# Global_Reg_PRM register map
Vendor: Texas Instruments
Peripheral module from a debugger description file (folder omap34xx).
Registers are 32-bit, access per field, reset values left out (the file's numbers can be read two ways) unless marked. A register's access mark holds for its fields unless they carry their own. Offsets are as the file gives them; lines under a group give offsets from that group; [hi:lo] are bit positions; {n}, {i} and the like mark numbered series; 'fields as' and 'values as' point back to an identical list; <NAME> marks a mode.

## Global_Reg_PRM
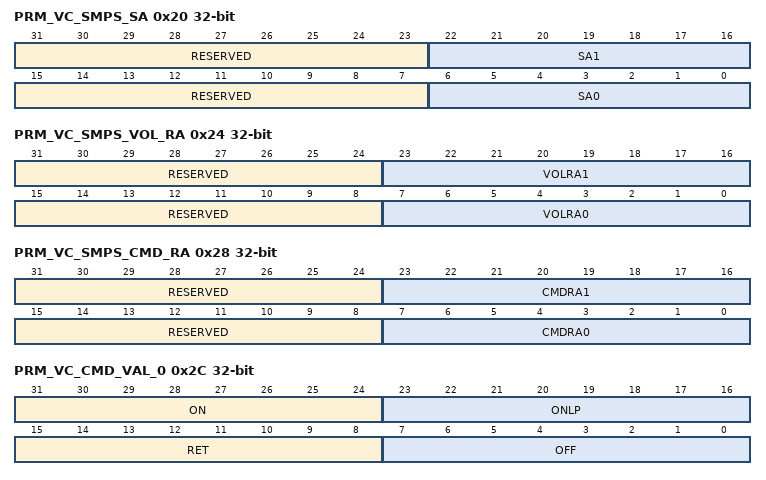
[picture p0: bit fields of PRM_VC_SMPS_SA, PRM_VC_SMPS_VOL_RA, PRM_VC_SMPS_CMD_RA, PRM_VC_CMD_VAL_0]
0x20 PRM_VC_SMPS_SA — This register allows the setting of the I2C slave address of the Power IC device.
  [31:23] RESERVED ro — Write 0s for future compatibility. Read is undefined.
  [22:16] SA1 rw — Set the IC slave address value for the second (if any) Power IC device.
  [15:7] RESERVED ro — Write 0s for future compatibility. Read is undefined.
  [6:0] SA0 rw — Set the IC slave address value for the first Power IC device.
0x24 PRM_VC_SMPS_VOL_RA — This register allows the setting of the voltage configuration register address for the VDD channels.
  [31:24] RESERVED ro — Write 0s for future compatibility. Read is undefined.
  [23:16] VOLRA1 rw — Set the voltage configuration register address value for the second VDD channel (VDD2).
  [15:8] RESERVED ro — Write 0s for future compatibility. Read is undefined.
  [7:0] VOLRA0 rw — Set the voltage configuration register address value for the first VDD channel (VDD1).
0x28 PRM_VC_SMPS_CMD_RA — This register allows the setting of the ON/Retention/OFF command configuration register address for the VDD channels. It is used if the Power IC device has different register addresses for voltage value and ON/Retention/OFF command.
  [31:24] RESERVED ro — Write 0s for future compatibility. Read is undefined.
  [23:16] CMDRA1 rw — Set the ON/ON-LP/Retention/OFF command configuration register address value for the second VDD channel (VDD2).
  [15:8] RESERVED ro — Write 0s for future compatibility. Read is undefined.
  [7:0] CMDRA0 rw — Set the ON/ON-LP/Retention/OFF command configuration register address value for the first VDD channel (VDD1).
0x2C PRM_VC_CMD_VAL_0 rw — This register allows the setting of the ON/Retention/OFF voltage level values for the first VDD channel.
  [31:24] ON — Set the ON voltage level value for the first VDD channel (VDD1).
  [23:16] ONLP — Set the ON-LP voltage level value for the first VDD channel (VDD1).
  [15:8] RET — Set the RET voltage level value for the first VDD channel (VDD1).
  [7:0] OFF — Set the OFF voltage level value for the first VDD channel (VDD1).
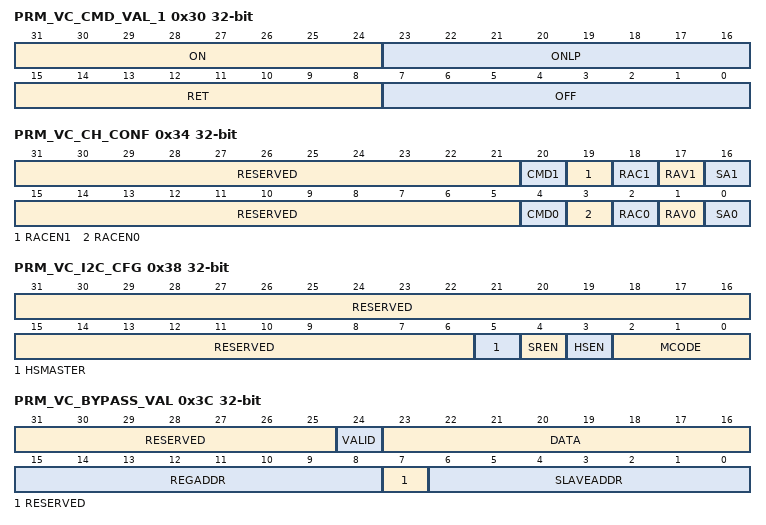
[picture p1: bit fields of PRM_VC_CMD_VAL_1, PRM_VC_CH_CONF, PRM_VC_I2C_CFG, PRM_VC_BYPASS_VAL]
0x30 PRM_VC_CMD_VAL_1 rw — This register allows the setting of the ON/Retention/OFF voltage level values for the second VDD channel. It is used if the second channel has different values than the first channel.
  [31:24] ON — Set the ON voltage level value for the second VDD channel (VDD2).
  [23:16] ONLP — Set the ON-LP voltage level value for the second VDD channel (VDD2).
  [15:8] RET — Set the RET voltage level value for the second VDD channel (VDD2).
  [7:0] OFF — Set the OFF voltage level value for the second VDD channel (VDD2).
0x34 PRM_VC_CH_CONF — This register allows the configuration pointers for both VDD channels.
  [31:21] RESERVED ro — Write 0s for future compatibility. Read is undefined.
  [20] CMD1 rw — Selects the ON/ON-LP/Retention/OFF voltage values for the second VDD channel (VDD2).
  [19] RACEN1 rw — Enable bit for usage of RAC1.
  [18] RAC1 rw — Set the ON/ON-LP/Retention/OFF command configuration register address pointer for the second VDD channel (VDD2).
  [17] RAV1 rw — Set the voltage configuration register address pointer for the second VDD channel (VDD2).
  [16] SA1 rw — Set the slave address pointer for the second VDD channel (VDD2).
  [15:5] RESERVED ro — Write 0s for future compatibility. Read is undefined.
  [4] CMD0 rw — Selects the ON/ON-LP/Retention/OFF voltage values for the first VDD channel (VDD1).
  [3] RACEN0 rw — Enable bit for usage of RAC0.
  [2] RAC0 rw — Set the ON/ON-LP/Retention/OFF command configuration register address pointer for the first VDD channel (VDD1).
  [1] RAV0 rw — Set the voltage configuration register address pointer for the first VDD channel (VDD1).
  [0] SA0 rw — Set the slave address pointer for the first VDD channel (VDD1).
0x38 PRM_VC_I2C_CFG — This register allows the configuration pointers for both VDD channels.
  [31:6] RESERVED ro — Write 0s for future compatibility. Read is undefined.
  [5] HSMASTER rw — Put the I2C pads in a low power mode in case of light load.
    0=Disables the I2C pads low power mode; 1=Enables the I2C pads low power mode
  [4] SREN rw — Enables the I2C repeated start operation mode.
    0=Disables the repeated start operation mode; 1=Enables the repeated start operation mode
  [3] HSEN rw — Enables I2C bus High Speed mode.
    0=Disables the I2C high speed mode; 1=Enables the I2C high speed mode
  [2:0] MCODE rw — Master code value for I2C High Speed preamble transmission.
0x3C PRM_VC_BYPASS_VAL rw — This register allows the programming of the Power IC device using the bypass interface.
  [31:25] RESERVED — Write 0s for future compatibility. Read is undefined.
  [24] VALID — This bit validates the bypass command. It is automatically cleared by HW either after getting the acknowledge back from the SMPS or if an error occured.
    0=The last command send has been acknowledged; 1=The Voltage Controller send the command to the I2C interface; 1=Pending command is being process
  [23:16] DATA — Data to send to the Power IC device.
  [15:8] REGADDR — Set the address of Power IC device register to configure.
  [7] RESERVED — Write 0s for future compatibility. Read is undefined.
  [6:0] SLAVEADDR — Set the I2C slave address value.
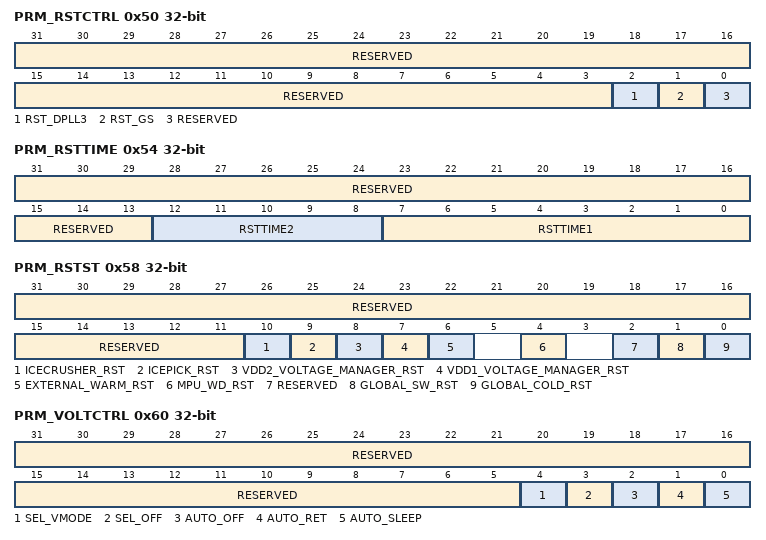
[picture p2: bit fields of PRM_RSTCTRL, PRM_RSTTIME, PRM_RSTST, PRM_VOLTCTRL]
0x50 PRM_RSTCTRL — Global software and DPLL3 reset control. This register is auto-cleared. Only write 1 is possible. A read returns 0 only.
  [31:3] RESERVED ro — Write 0s for future compatibility. Read returns 0.
  [2] RST_DPLL3 rw — DPLL3 software reset control. This bit is reset only upon a global cold source of reset.
    0=DPLL3 software reset is cleared; 1=Asserts the DPLL3 software reset and induces a global cold reset on the whole chip. The software must ensure the SDRAM is properly put in sef-refresh mode before applying this reset.
  [1] RST_GS rw — Global software reset control. This bit is reset upon any global source of reset (warm and cold).
    0=Global software reset is cleared; 1=Asserts a global software reset
  [0] RESERVED ro — Write 0s for future compatibility. Read returns 0.
0x54 PRM_RSTTIME — Reset duration control.
  [31:13] RESERVED ro — Write 0s for future compatibility. Read returns 0.
  [12:8] RSTTIME2 rw — (Power domain) reset duration 2(number of RM_ICLK clock cycles)
  [7:0] RSTTIME1 rw — (Global) reset duration 1(number of Func_32k.clk clock cycles)
0x58 PRM_RSTST — This register logs the global reset sources. Each bit is set upon release of the domain reset signal. Must be cleared by software.
  [31:11] RESERVED ro — Write 0s for future compatibility. Read returns 0.
  [10] ICECRUSHER_RST rw — IceCrusher reset event. This is a source of warm reset initiated by the emulation.
    0=ICECRUSHER_RST_0_r (No IceCrusher reset.); 0=ICECRUSHER_RST_0_w (Status bit unchanged); 1=ICECRUSHER_RST_1_r (IceCrusher reset occurred.); 1=ICECRUSHER_RST_1_w (Status bit is cleared to 0.)
  [9] ICEPICK_RST rw — IcePick reset event. This is a source of warm reset initiated by the emulation.
    0=ICEPICK_RST_0_r (No IcePick reset.); 0=ICEPICK_RST_0_w (Status bit unchanged); 1=ICEPICK_RST_1_r (IcePick reset occurred.); 1=ICEPICK_RST_1_w (Status bit is cleared to 0.)
  [8] VDD2_VOLTAGE_MANAGER_RST rw — VDD2 voltage manager reset event
    0=VDD2_VOLTAGE_MANAGER_RST_0_r (No VDD2 voltage manager reset.); 0=VDD2_VOLTAGE_MANAGER_RST_0_w (Status bit unchanged); 1=VDD2_VOLTAGE_MANAGER_RST_1_r (VDD2 voltage manager reset occurred.); 1=VDD2_VOLTAGE_MANAGER_RST_1_w (Status bit is cleared to 0.)
  [7] VDD1_VOLTAGE_MANAGER_RST rw — VDD1 voltage manager reset event
    0=VDD1_VOLTAGE_MANAGER_RST_0_r (No VDD1 voltage manager reset.); 0=VDD1_VOLTAGE_MANAGER_RST_0_w (Status bit unchanged); 1=VDD1_VOLTAGE_MANAGER_RST_1_r (VDD1 voltage manager reset occurred.); 1=VDD1_VOLTAGE_MANAGER_RST_1_w (Status bit is cleared to 0.)
  [6] EXTERNAL_WARM_RST rw — External warm reset event
    0=EXTERNAL_WARM_RST_0_r (No global warm reset.); 0=EXTERNAL_WARM_RST_0_w (Status bit unchanged); 1=EXTERNAL_WARM_RST_1_r (Global external warm reset occurred.); 1=EXTERNAL_WARM_RST_1_w (Status bit is cleared to 0.)
  [4] MPU_WD_RST rw — MPU watchdog reset event
    0=MPU_WD_RST_0_r (No MPU watchdog reset.); 0=MPU_WD_RST_0_w (Status bit unchanged); 1=MPU_WD_RST_1_r (MPU wachtdog reset occurred.); 1=MPU_WD_RST_1_w (Status bit is cleared to 0.)
  [2] RESERVED ro — Write 0s for future compatibility. Read returns 0.
  [1] GLOBAL_SW_RST rw — Global software reset event
    0=GLOBAL_SW_RST_0_r (No global software reset.); 0=GLOBAL_SW_RST_0_w (Status bit unchanged); 1=GLOBAL_SW_RST_1_r (Global software reset occurred.); 1=GLOBAL_SW_RST_1_w (Status bit is cleared to 0.)
  [0] GLOBAL_COLD_RST rw — Power-up (cold) reset event
    0=GLOBAL_COLD_RST_0_r (No power-on reset.); 0=GLOBAL_COLD_RST_0_w (Status bit unchanged); 1=GLOBAL_COLD_RST_1_r (Power-on reset occurred.); 1=GLOBAL_COLD_RST_1_w (Status bit is cleared to 0.)
0x60 PRM_VOLTCTRL — This register allows a direct control on the external power IC.
  [31:5] RESERVED ro — Write 0s for future compatibility. Read returns 0.
  [4] SEL_VMODE rw — This bit allows to select the mode used to control the Power IC (I2C or VMODE).
    0=The Power IC is controlled through the I2C interface; 1=The Power IC is controlled through the VMODE interface
  [3] SEL_OFF rw — This bit allows to select the mode used to send the OFF command.
    0=The OFF command is sent through the voltage controller I2C interface; 1=The signal SYS.OFF_MODE is asserted
  [2] AUTO_OFF rw — This bit allows to send an OFF command to the Power IC.
    0=The OFF command is not sent; 1=The OFF command is automatically send when the voltage domain is in the appropriate standby mode
  [1] AUTO_RET rw — This bit allows to send a RETENTION command to the Power IC through the voltage controller I2C interface.
    0=The RETENTION command is not sent; 1=The RETENTION command is automatically send when the voltage domain is in the appropriate standby mode
  [0] AUTO_SLEEP rw — This bit allows to send a SLEEP command to the Power IC through the voltage controller I2C interface.
    0=The SLEEP command is not sent; 1=The SLEEP command is automatically send when the voltage domain is in the appropriate standby mode
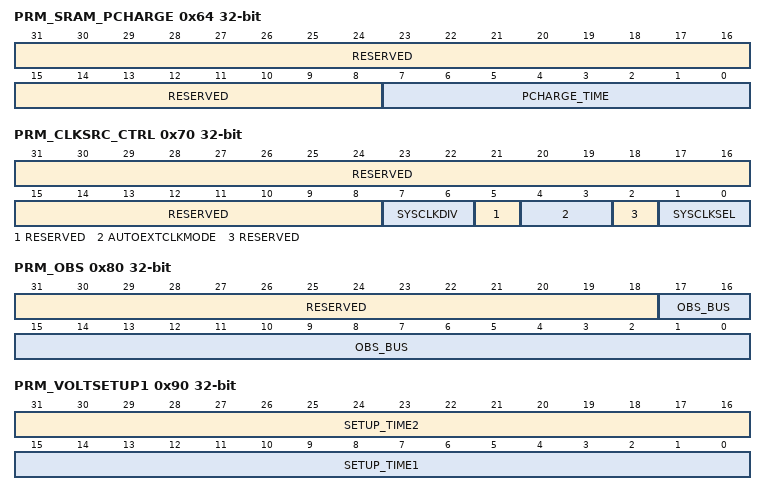
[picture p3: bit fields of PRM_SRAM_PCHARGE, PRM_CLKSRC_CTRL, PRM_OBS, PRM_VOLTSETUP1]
0x64 PRM_SRAM_PCHARGE — This register allows setting the pre-charge time of the SRAM.
  [31:8] RESERVED ro — Write 0s for future compatibility. Read returns 0.
  [7:0] PCHARGE_TIME rw — Number of system clock cycles for the SRAM pre-charge duration.
0x70 PRM_CLKSRC_CTRL — This register provides control over the device source clock.
  [31:8] RESERVED ro — Write 0s for future compatibility. Read returns 0.
  [7:6] SYSCLKDIV rw — This field controls the system clock input divider
    1=Syst_clk is external clock / 1; 2=Syst_clk is external clock / 2
  [5] RESERVED ro — Write 0s for future compatibility. Read returns 0.
  [4:3] AUTOEXTCLKMODE rw — This field allows to control the external clock request (CLKREQ) and the oscillator
    0=CLKREQ is kept asserted or the oscillator is always active (in master mode); 1=CLKREQ is de-asserted or the oscillator is put in power-down mode (in master mode) when all the voltages domains are SLEEP, RETENTION or OFF states; 2=CLKREQ is de-asserted or the oscillator is put in power-down mode (in master mode) when all the voltages domains are RETENTION or OFF states; 3=CLKREQ is de-asserted or the oscillator is put in power-down mode (in master mode) only when all the voltage domains are in OFF states
  [2] RESERVED ro — Write 0s for future compatibility. Read returns 0.
  [1:0] SYSCLKSEL ro — This field reflects the mode of the ocillator. It is automatically set accordingly to the external tied-off configuration and its value is unsignificant before the release of the power-on reset.
    0=Bypass mode: the system clock is issued from an external square clock source; 1=Oscillator mode: the system clock is issued from an external quartz; 3=Unknow state (not know before release of the power-on reset)
0x80 PRM_OBS ro — This register logs the observable signals (18 bits). This register is intended to be read through the debugger interface when the device is in OFF mode.
  [31:18] RESERVED — Read is undefined.
  [17:0] OBS_BUS — Indicates the current value on the observable bus.
0x90 PRM_VOLTSETUP1 rw — This register allows setting the setup time of the VDD1 and VDD2 regulators. This register is used when exiting off/retention/sleep mode (or entering off/retention/sleep mode) and when OMAP manages the sequencing of the voltages regulation steps.
  [31:16] SETUP_TIME2 — The value, in number of cycles of SYS_CLK, determines the setup duration of VDD2 regulator. The setup duration is computed as = 8 x number of cycles of SYS_CLK set in the register bit field.
  [15:0] SETUP_TIME1 — The value, in number of cycles of SYS_CLK, determines the setup duration of VDD1 regulator. The setup duration is computed as = 8 x number of cycles of SYS_CLK set in the register bit field.
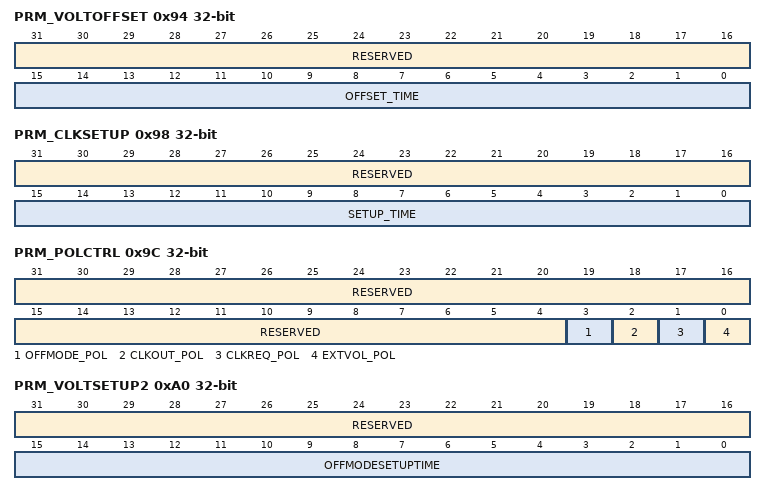
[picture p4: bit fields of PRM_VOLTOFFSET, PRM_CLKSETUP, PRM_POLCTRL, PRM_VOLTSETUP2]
0x94 PRM_VOLTOFFSET — This register allows controlling the sys_offmode signal upon wake-up from OFF mode when the OFF sequence is supervised by the Power IC. This register allows setting the offset-time to de-assert sys_offmode when exiting the OFF mode.
  [31:16] RESERVED ro — Write 0s for future compatibility. Read returns 0.
  [15:0] OFFSET_TIME rw — Number of 32kHz clock cycles for the OFF mode offset time
0x98 PRM_CLKSETUP — This register allows setting the setup time of the oscillator system clock (sys_clk), based on number of 32 kHz clock cycles.
  [31:16] RESERVED ro — Write 0s for future compatibility. Read returns 0.
  [15:0] SETUP_TIME rw — Number of 32kHz clock cycles for the SETUP duration
0x9C PRM_POLCTRL — This register allows setting the polarity of device outputs control signals.
  [31:4] RESERVED ro — Write 0s for future compatibility. Read returns 0.
  [3] OFFMODE_POL rw — Controls the polarity of the sys_offmode signal
    0=sys_offmode is active low; 1=sys_offmode is active high
  [2] CLKOUT_POL rw — Controls the external output clock polarity when disabled
    0=sys_clkout is gated low when inactive; 1=sys_clkout is gated high when inactive
  [1] CLKREQ_POL rw — Controls the polarity of the sys_clkreq signal
    0=sys_clkreq is active low; 1=sys_clkreq is active high
  [0] EXTVOL_POL rw — Controls the polarity of sys_vmode signal
    0=sys_vmode signal is active low; 1=sys_vmode signal is active high
0xA0 PRM_VOLTSETUP2 — This register allows setting the overall setup time of VDD1 and VDD2 regulators. This register is used when exiting OFF mode and when the Power IC manages the sequencing of the voltages regulation steps.
  [31:16] RESERVED ro — Write 0s for future compatibility. Read returns 0.
  [15:0] OFFMODESETUPTIME rw — Number of 32kHz clock cycles for the overall setup time of VDD1 and VDD2 regulators.
